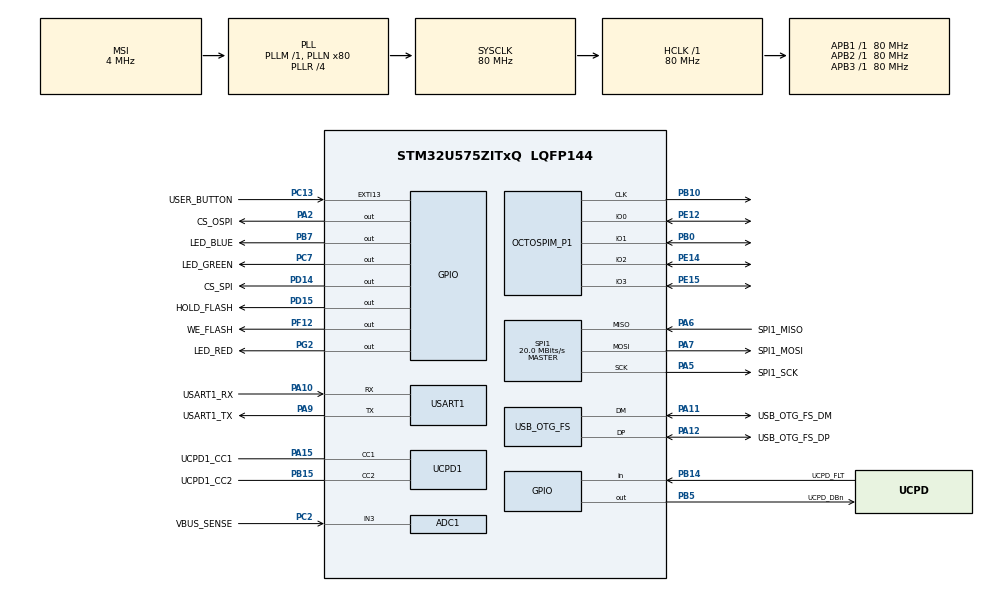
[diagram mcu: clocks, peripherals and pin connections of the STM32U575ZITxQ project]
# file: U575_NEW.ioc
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ADC1.NbrOfConversion=1
ADC1.Resolution=ADC_RESOLUTION_14B
ADC1.master=1
CORTEX_M33_NS.userName=CORTEX_M33
Mcu.Family=STM32U5
Mcu.Name=STM32U575ZITxQ
Mcu.Package=LQFP144
NVIC.ICACHE_IRQn=true\:0\:0\:false\:false\:true\:true\:true\:true
NVIC.OTG_FS_IRQn=true\:0\:0\:false\:false\:true\:true\:true\:true
NVIC.PriorityGroup=NVIC_PRIORITYGROUP_3
OCTOSPI1.ChipSelectHighTime=6
OCTOSPI1.ClockPrescaler=2
OCTOSPI1.DeviceSize=27
OCTOSPI1.MemoryType=HAL_OSPI_MEMTYPE_MICRON
OCTOSPI1.SampleShifting=HAL_OSPI_SAMPLE_SHIFTING_NONE
PA10.GPIO_Label=USART1_RX
PA10.GPIO_PuPd=GPIO_PULLDOWN
PA10.GPIO_Speed=GPIO_SPEED_FREQ_VERY_HIGH
PA10.Mode=Asynchronous
PA10.PinAttribute=Free
PA10.Signal=USART1_RX
PA11.GPIO_Label=USB_OTG_FS_DM
PA11.GPIO_Speed=GPIO_SPEED_FREQ_VERY_HIGH
PA11.Mode=Device_Only
PA11.PinAttribute=Free
PA11.Signal=USB_OTG_FS_DM
PA12.GPIO_Label=USB_OTG_FS_DP
PA12.GPIO_Speed=GPIO_SPEED_FREQ_VERY_HIGH
PA12.Mode=Device_Only
PA12.PinAttribute=Free
PA12.Signal=USB_OTG_FS_DP
PA13\ (JTMS/SWDIO).Mode=Trace_Asynchronous_SW
PA13\ (JTMS/SWDIO).PinAttribute=Free
PA13\ (JTMS/SWDIO).Signal=DEBUG_JTMS-SWDIO
PA14\ (JTCK/SWCLK).Mode=Trace_Asynchronous_SW
PA14\ (JTCK/SWCLK).PinAttribute=Free
PA14\ (JTCK/SWCLK).Signal=DEBUG_JTCK-SWCLK
PA15\ (JTDI).GPIO_Label=UCPD1_CC1
PA15\ (JTDI).Mode=Sink_AllSignals
PA15\ (JTDI).PinAttribute=Free
PA15\ (JTDI).Signal=UCPD1_CC1
PA2.GPIO_Label=CS_OSPI
PA2.GPIO_ModeDefaultOutputPP=GPIO_MODE_OUTPUT_PP
PA2.GPIO_PuPd=GPIO_PULLUP
PA2.GPIO_Speed=GPIO_SPEED_FREQ_VERY_HIGH
PA2.PinState=GPIO_PIN_SET
PA2.Signal=GPIO_Output
PA5.GPIO_Label=SPI1_SCK
PA5.GPIO_Speed=GPIO_SPEED_FREQ_HIGH
PA5.Mode=Full_Duplex_Master
PA5.Signal=SPI1_SCK
PA6.GPIO_Label=SPI1_MISO
PA6.GPIO_Speed=GPIO_SPEED_FREQ_HIGH
PA6.Mode=Full_Duplex_Master
PA6.Signal=SPI1_MISO
PA7.GPIO_Label=SPI1_MOSI
PA7.GPIO_Speed=GPIO_SPEED_FREQ_HIGH
PA7.Mode=Full_Duplex_Master
PA7.PinAttribute=Free
PA7.Signal=SPI1_MOSI
PA9.GPIO_Label=USART1_TX
PA9.GPIO_PuPd=GPIO_PULLDOWN
PA9.GPIO_Speed=GPIO_SPEED_FREQ_VERY_HIGH
PA9.Mode=Asynchronous
PA9.PinAttribute=Free
PA9.Signal=USART1_TX
PB0.Mode=OCTOSPI1_IOL_Port1L_30_MX
PB0.Signal=OCTOSPIM_P1_IO1
PB10.Mode=O1_P1_CLK_MX
PB10.Signal=OCTOSPIM_P1_CLK
PB14.GPIO_Label=UCPD_FLT
PB14.PinAttribute=Free
PB14.Signal=GPIO_Input
PB15.GPIO_Label=UCPD1_CC2
PB15.Mode=Sink_AllSignals
PB15.PinAttribute=Free
PB15.Signal=UCPD1_CC2
PB3\ (JTDO/TRACESWO).Mode=Trace_Asynchronous_SW
PB3\ (JTDO/TRACESWO).PinAttribute=Free
PB3\ (JTDO/TRACESWO).Signal=DEBUG_JTDO-SWO
PB5.GPIO_Label=UCPD_DBn
PB5.PinAttribute=Free
PB5.Signal=GPIO_Output
PB7.GPIO_Label=LED_BLUE
PB7.GPIO_ModeDefaultOutputPP=GPIO_MODE_OUTPUT_PP
PB7.GPIO_PuPd=GPIO_PULLUP
PB7.GPIO_Speed=GPIO_SPEED_FREQ_HIGH
PB7.PinAttribute=Free
PB7.Signal=GPIO_Output
PC13.GPIO_Label=USER_BUTTON
PC13.GPIO_ModeDefaultEXTI=GPIO_MODE_IT_FALLING
PC13.PinAttribute=Free
PC13.Signal=GPXTI13
PC14-OSC32_IN\ (PC14).Mode=LSE-External-Oscillator
PC14-OSC32_IN\ (PC14).Signal=RCC_OSC32_IN
PC15-OSC32_OUT\ (PC15).Mode=LSE-External-Oscillator
PC15-OSC32_OUT\ (PC15).Signal=RCC_OSC32_OUT
PC2.GPIO_Label=VBUS_SENSE
PC2.Mode=IN3-Single-Ended
PC2.PinAttribute=Free
PC2.Signal=ADC1_IN3
PC7.GPIO_Label=LED_GREEN
PC7.GPIO_PuPd=GPIO_PULLUP
PC7.GPIO_Speed=GPIO_SPEED_FREQ_HIGH
PC7.PinAttribute=Free
PC7.Signal=GPIO_Output
PD14.GPIO_Label=CS_SPI
PD14.GPIO_Speed=GPIO_SPEED_FREQ_HIGH
PD14.PinAttribute=Free
PD14.PinState=GPIO_PIN_SET
PD14.Signal=GPIO_Output
PD15.GPIO_Label=HOLD_FLASH
PD15.GPIO_Speed=GPIO_SPEED_FREQ_MEDIUM
PD15.PinState=GPIO_PIN_SET
PD15.Signal=GPIO_Output
PE12.Mode=OCTOSPI1_IOL_Port1L_30_MX
PE12.Signal=OCTOSPIM_P1_IO0
PE14.GPIO_PuPd=GPIO_PULLUP
PE14.Mode=OCTOSPI1_IOL_Port1L_30_MX
PE14.Signal=OCTOSPIM_P1_IO2
PE15.GPIO_PuPd=GPIO_PULLUP
PE15.Mode=OCTOSPI1_IOL_Port1L_30_MX
PE15.Signal=OCTOSPIM_P1_IO3
PF12.GPIO_Label=WE_FLASH
PF12.GPIO_Speed=GPIO_SPEED_FREQ_MEDIUM
PF12.PinState=GPIO_PIN_SET
PF12.Signal=GPIO_Output
PG2.GPIO_Label=LED_RED
PG2.Signal=GPIO_Output
PWR.PowerMode=PWR_SMPS_SUPPLY
ProjectManager.HeapSize=0x200
ProjectManager.StackSize=0x400
ProjectManager.TargetToolchain=MDK-ARM V5.32
RCC.ADCFreq_Value=16000000
RCC.AHBFreq_Value=80000000
RCC.APB1Freq_Value=80000000
RCC.APB1TimFreq_Value=80000000
RCC.APB2Freq_Value=80000000
RCC.APB2TimFreq_Value=80000000
RCC.APB3Freq_Value=80000000
RCC.CortexFreq_Value=80000000
RCC.DACCLockSelectionVirtual=RCC_DAC1CLKSOURCE_LSI
RCC.DACCLockSelectionVirtualString=RCC_DAC1CLKSOURCE_LSI
RCC.EPOD_VALUE=4000000
RCC.HCLKFreq_Value=80000000
RCC.HSE_VALUE=16000000
RCC.HSI48_VALUE=48000000
RCC.HSI_VALUE=16000000
RCC.LSIDIV_VALUE=32000
RCC.MSI_VALUE=4000000
RCC.PLL1R=4
RCC.PLLN=80
RCC.SPI1CLockSelection=RCC_SPI1CLKSOURCE_PCLK2
RCC.SYSCLKFreq_VALUE=80000000
RCC.SYSCLKSource=RCC_SYSCLKSOURCE_PLLCLK
RCC.USBFreq_Value=48000000
RCC.VCOOutputFreq_Value=320000000
RCC.VDD_VALUE=3.3
SPI1.BaudRatePrescaler=SPI_BAUDRATEPRESCALER_4
SPI1.CLKPolarity=SPI_POLARITY_LOW
SPI1.CRCCalculation=SPI_CRCCALCULATION_DISABLE
SPI1.CalculateBaudRate=20.0 MBits/s
SPI1.DataSize=SPI_DATASIZE_8BIT
SPI1.Direction=SPI_DIRECTION_2LINES
SPI1.FifoThreshold=SPI_FIFO_THRESHOLD_01DATA
SPI1.IOSwap=SPI_IO_SWAP_DISABLE
SPI1.MasterInterDataIdleness=SPI_MASTER_INTERDATA_IDLENESS_00CYCLE
SPI1.MasterKeepIOState=SPI_MASTER_KEEP_IO_STATE_DISABLE
SPI1.MasterReceiverAutoSusp=SPI_MASTER_RX_AUTOSUSP_DISABLE
SPI1.MasterSSIdleness=SPI_MASTER_SS_IDLENESS_00CYCLE
SPI1.Mode=SPI_MODE_MASTER
SPI1.NSSPMode=SPI_NSS_PULSE_DISABLE
SPI1.TriggerState=SPI_AUTO_MODE_DISABLE
SPI1.VirtualType=VM_MASTER
USART1.VirtualMode-Asynchronous=VM_ASYNC
USB_OTG_FS.VirtualMode=Device_Only
VP_ICACHE_VS_ICACHE.Mode=DirectMappedCache
VP_LPBAMQUEUE_VS_QUEUE.Mode=QUEUEMODE
VP_LPBAM_VS_SIG1.Mode=SmartRun
VP_LPBAM_VS_SIG4.Mode=LPDMA1
VP_OCTOSPI1_VS_quad_mx.Mode=quad_mode_mx
VP_PWR_VS_DBSignals.Mode=DisableDeadBatterySignals
VP_PWR_VS_LPOM.Mode=PowerOptimisation
VP_PWR_VS_SECSignals.Mode=Security/Privilege
board=NUCLEO-U575ZI-Q

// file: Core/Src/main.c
/* USER CODE BEGIN Header */
/**
  ******************************************************************************
  * @file           : main.c
  * @brief          : Main program body
  ******************************************************************************
  * @attention
  *
  * Copyright (c) 2023 STMicroelectronics.
  * All rights reserved.
  *
  * This software is licensed under terms that can be found in the LICENSE file
  * in the root directory of this software component.
  * If no LICENSE file comes with this software, it is provided AS-IS.
  *
  ******************************************************************************
  */
/* USER CODE END Header */
#include "main.h"
#include "adc.h"
#include "icache.h"
#include "octospi.h"
#include "spi.h"
#include "ucpd.h"
#include "usart.h"
#include "usb_otg.h"
#include "gpio.h"

/* USER CODE BEGIN PM */
#define ID_COMMAND 0x9F
#define ID_SIZE 3
// #define DATAS 3
// uint16_t CA[]={0x00,0x00};
 //uint8_t CA2=0x00;
//uint16_t PAGE;
/* USER CODE END PM */

/* USER CODE BEGIN PV */
uint8_t id[ID_SIZE];
uint8_t k=1;
//uint8_t rxData1[10] = {0}; // Buffer to store the received data
//uint8_t bi=1;
//uint8_t bi1 =1;

/* USER CODE END PV */

void SystemClock_Config(void);
static void SystemPower_Config(void);

int main(void)
{

  /* MCU Configuration--------------------------------------------------------*/

  /* Reset of all peripherals, Initializes the Flash interface and the Systick. */
  HAL_Init();

  /* Configure the system clock */
  SystemClock_Config();

  /* Configure the System Power */
  SystemPower_Config();

  /* Initialize all configured peripherals */
  MX_GPIO_Init();
  MX_ADC1_Init();
  MX_SPI1_Init();
  MX_UCPD1_Init();
  MX_USART1_UART_Init();
  MX_USB_OTG_FS_PCD_Init();
  MX_ICACHE_Init();
  MX_OCTOSPI1_Init();
  /* USER CODE BEGIN 2 */
 // OSPI_Reset_W25M02();
//OSPI_Erase128K_W25M02IG();

   //OSPI_WRITE_W25M02IG();

  /* USER CODE END 2 */

  /* Infinite loop */
  /* USER CODE BEGIN WHILE */
  while (1)
  {
		//uint8_t Buffer_2048[2048]={0};
//	OSPI_Reset_W25M02();
	//	OSPI_WRITE_W25M02IG();
		OSPI_READ_W25M02IG();
		// OSPI_READ_Register();
	  //	OctaSPI_GetID();
	 //  Write_Protection_SoftorHard();
	 //	 SPI1_Write_W25M02IG();
	 // SPI1_Read_W25M02IG();
		//W25M02_ReadID();

    /* USER CODE END WHILE */

  }
}

void SystemClock_Config(void)
{
  RCC_OscInitTypeDef RCC_OscInitStruct = {0};
  RCC_ClkInitTypeDef RCC_ClkInitStruct = {0};

  /** Configure the main internal regulator output voltage
  */
  if (HAL_PWREx_ControlVoltageScaling(PWR_REGULATOR_VOLTAGE_SCALE2) != HAL_OK)
  {
    Error_Handler();
  }

  /** Initializes the CPU, AHB and APB buses clocks
  */
  RCC_OscInitStruct.OscillatorType = RCC_OSCILLATORTYPE_HSI48|RCC_OSCILLATORTYPE_HSI
                              |RCC_OSCILLATORTYPE_MSI;
  RCC_OscInitStruct.HSIState = RCC_HSI_ON;
  RCC_OscInitStruct.HSI48State = RCC_HSI48_ON;
  RCC_OscInitStruct.HSICalibrationValue = RCC_HSICALIBRATION_DEFAULT;
  RCC_OscInitStruct.MSIState = RCC_MSI_ON;
  RCC_OscInitStruct.MSICalibrationValue = RCC_MSICALIBRATION_DEFAULT;
  RCC_OscInitStruct.MSIClockRange = RCC_MSIRANGE_4;
  RCC_OscInitStruct.PLL.PLLState = RCC_PLL_ON;
  RCC_OscInitStruct.PLL.PLLSource = RCC_PLLSOURCE_MSI;
  RCC_OscInitStruct.PLL.PLLMBOOST = RCC_PLLMBOOST_DIV1;
  RCC_OscInitStruct.PLL.PLLM = 1;
  RCC_OscInitStruct.PLL.PLLN = 80;
  RCC_OscInitStruct.PLL.PLLP = 2;
  RCC_OscInitStruct.PLL.PLLQ = 2;
  RCC_OscInitStruct.PLL.PLLR = 4;
  RCC_OscInitStruct.PLL.PLLRGE = RCC_PLLVCIRANGE_0;
  RCC_OscInitStruct.PLL.PLLFRACN = 0;
  if (HAL_RCC_OscConfig(&RCC_OscInitStruct) != HAL_OK)
  {
    Error_Handler();
  }

  /** Initializes the CPU, AHB and APB buses clocks
  */
  RCC_ClkInitStruct.ClockType = RCC_CLOCKTYPE_HCLK|RCC_CLOCKTYPE_SYSCLK
                              |RCC_CLOCKTYPE_PCLK1|RCC_CLOCKTYPE_PCLK2
                              |RCC_CLOCKTYPE_PCLK3;
  RCC_ClkInitStruct.SYSCLKSource = RCC_SYSCLKSOURCE_PLLCLK;
  RCC_ClkInitStruct.AHBCLKDivider = RCC_SYSCLK_DIV1;
  RCC_ClkInitStruct.APB1CLKDivider = RCC_HCLK_DIV1;
  RCC_ClkInitStruct.APB2CLKDivider = RCC_HCLK_DIV1;
  RCC_ClkInitStruct.APB3CLKDivider = RCC_HCLK_DIV1;

  if (HAL_RCC_ClockConfig(&RCC_ClkInitStruct, FLASH_LATENCY_2) != HAL_OK)
  {
    Error_Handler();
  }
}

/**
  * @brief Power Configuration
  * @retval None
  */
static void SystemPower_Config(void)
{
  HAL_PWREx_EnableVddIO2();

  /*
   * Switch to SMPS regulator instead of LDO
   */
  if (HAL_PWREx_ConfigSupply(PWR_SMPS_SUPPLY) != HAL_OK)
  {
    Error_Handler();
  }
}

void Error_Handler(void)
{
  __disable_irq();
  while (1)
  {
  }
}
